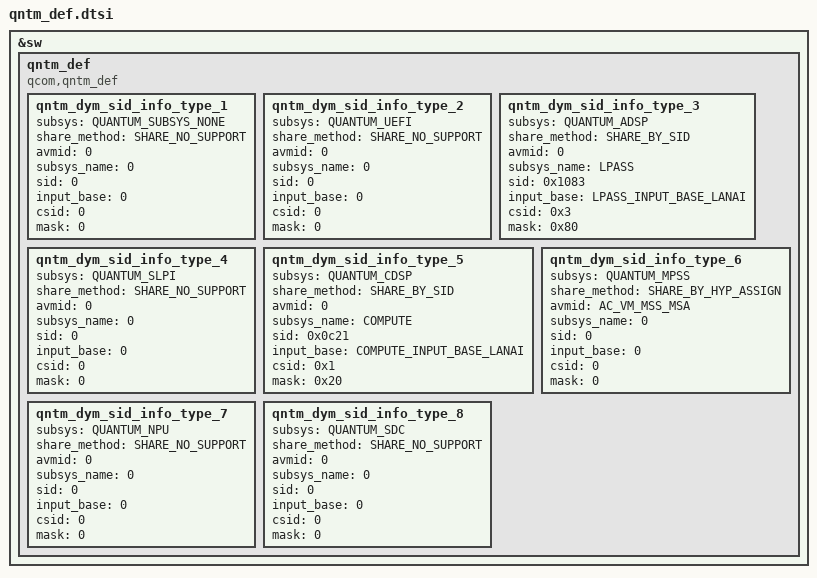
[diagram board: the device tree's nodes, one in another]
/**

This is the configuration file for Quantum sid mapping 

Copyright (c) 2023 by Qualcomm Technologies, Inc.  All Rights Reserved.
Confidential and Proprietary - Qualcomm Technologies, Inc.

**/

#include <qntm_defines.h>
#include <qntm_defines_common.h>
&sw {
	qntm_def {

		compatible = "qcom,qntm_def";
		
		qntm_dym_sid_info_type_1 {
			subsys                = <QUANTUM_SUBSYS_NONE>;
			share_method          = <SHARE_NO_SUPPORT>;
			avmid                 = <0>;
			subsys_name           = <0>;
			sid                   = <0>;
			input_base            = <0>;
			csid                  = <0>;
			mask                  = <0>;
		};
		qntm_dym_sid_info_type_2 {
			subsys                = <QUANTUM_UEFI>;
			share_method          = <SHARE_NO_SUPPORT>;
			avmid                 = <0>;
			subsys_name           = <0>;
			sid                   = <0>;
			input_base            = <0>;
			csid                  = <0>;
			mask                  = <0>;
		};
		qntm_dym_sid_info_type_3 {
			subsys                = <QUANTUM_ADSP>;
			share_method          = <SHARE_BY_SID>;
			avmid                 = <0>;
			subsys_name           = "LPASS";
			sid                   = <0x1083>;
			input_base            = <LPASS_INPUT_BASE_LANAI>;
			csid                  = <0x3>;
			mask                  = <0x80>;
		};
		qntm_dym_sid_info_type_4 {
			subsys                = <QUANTUM_SLPI>;
			share_method          = <SHARE_NO_SUPPORT>;
			avmid                 = <0>;
			subsys_name           = <0>;
			sid                   = <0>;
			input_base            = <0>;
			csid                  = <0>;
			mask                  = <0>;
		};
		qntm_dym_sid_info_type_5 {
			subsys                = <QUANTUM_CDSP>;
			share_method          = <SHARE_BY_SID>;
			avmid                 = <0>;
			subsys_name           = "COMPUTE";
			sid                   = <0x0c21>;
			input_base            = <COMPUTE_INPUT_BASE_LANAI>;
			csid                  = <0x1>;
			mask                  = <0x20>;
		};
		qntm_dym_sid_info_type_6 {
			subsys                = <QUANTUM_MPSS>;
			share_method          = <SHARE_BY_HYP_ASSIGN>;
			avmid                 = <AC_VM_MSS_MSA>;
			subsys_name           = <0>;
			sid                   = <0>;
			input_base             = <0>;
			csid                  = <0>;
			mask                  = <0>;
		};
		qntm_dym_sid_info_type_7 {
			subsys                = <QUANTUM_NPU>;
			share_method          = <SHARE_NO_SUPPORT>;
			avmid                 = <0>;
			subsys_name           = <0>;
			sid                   = <0>;
			input_base            = <0>;
			csid                  = <0>;
			mask                  = <0>;
		};
		qntm_dym_sid_info_type_8 {
			subsys                = <QUANTUM_SDC>;
			share_method          = <SHARE_NO_SUPPORT>;
			avmid                 = <0>;
			subsys_name           = <0>;
			sid                   = <0>;
			input_base            = <0>;
			csid                  = <0>;
			mask                  = <0>;
		};
	};
};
